# EQEP0_REG register map
Vendor: Texas Instruments
Peripheral module from a debugger description file (folder J7VCL).
Registers are 32-bit, read-write, reset 0x0 unless marked. A register's access mark holds for its fields unless they carry their own. Offsets are as the file gives them; lines under a group give offsets from that group; [hi:lo] are bit positions; {n}, {i} and the like mark numbered series; 'fields as' and 'values as' point back to an identical list; <NAME> marks a mode.

## EQEP0_REG
0x00 EQEP_QPOSCNT — QEP Position Counter register
  [31:0] POSCNT — This 32-bit Position Counter register counts up/down on every QEP pulse based on direction input.
0x04 EQEP_QPOSINIT — Position Counter Initialization register
  [31:0] INITPOS — This register contains the position value to be used to initialize the Position Counter based on external strobe or Index event.
0x08 EQEP_QPOSMAX — Maximum Position Count register
  [31:0] MAXPOS — This register contains the maximum Position Counter value for error checking in index reset mode or to reset the Position Counter based on the maximum count value.
0x0C EQEP_QPOSCMP — Position Compare register
  [31:0] POSCMP — Position compare value in this register is compared with the Position Counter (
0x10 EQEP_QPOSILAT ro — Index Position Latch register
  [31:0] IPOSLAT — Position Counter value can be latched into this register on index event as defined by the
0x14 EQEP_QPOSSLAT ro — Strobe Position Latch register
  [31:0] SPOSLAT — Position Counter value can be latched into this register on strobe event as defined by the
0x18 EQEP_QPOSLAT ro — QEP Position Counter Latch register
  [31:0] POSLAT — Position Counter value can be latched into this register on unit time out event.
0x1C EQEP_QUTMR — QEP Unit Timer register
  [31:0] UNITTMR — This register acts as time base for unit time event generation.
0x20 EQEP_QUPRD — QEP Unit Period register
  [31:0] UNITPRD — This register contains the period count for unit timer to generate periodic unit time events to latch the EQEP position information at periodic interval and optionally to generate interrupt.
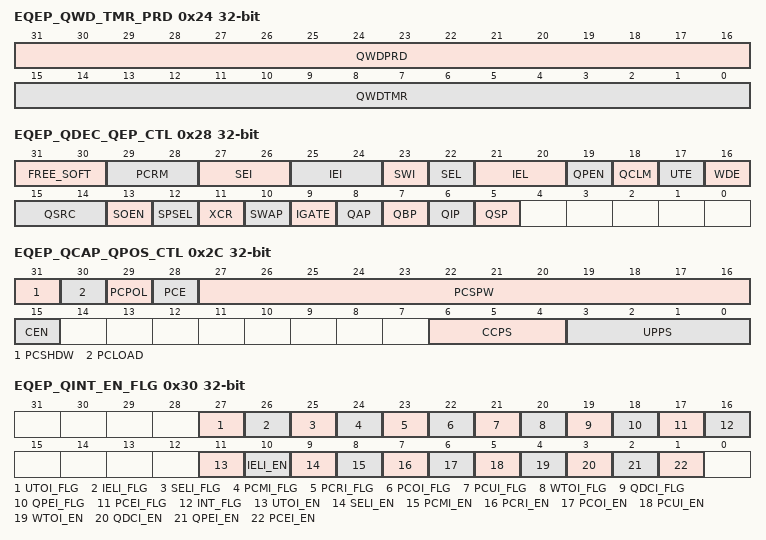
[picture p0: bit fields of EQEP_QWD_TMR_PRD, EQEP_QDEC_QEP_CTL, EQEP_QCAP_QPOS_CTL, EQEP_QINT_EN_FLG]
0x24 EQEP_QWD_TMR_PRD — QEP Watchdog Timer and Period register
  [31:16] QWDPRD — This field contains the time-out count for the QEP peripheral watch dog timer.
  [15:0] QWDTMR — This field acts as time base for watch dog to detect stalls.
0x28 EQEP_QDEC_QEP_CTL access per field — Quadrature Decoder and QEP Control register
  [31:30] FREE_SOFT rw — POSCNT Behavior:
  [29:28] PCRM rw — Position Counter Reset Mode:
  [27:26] SEI rw — Strobe Event Initialization of Position Counter:
  [25:24] IEI rw — Index Event Initialization of Position Counter:
  [23] SWI rw — Software Initialization of Position Counter:
  [22] SEL rw — Strobe Event Latch of Position Counter:
  [21:20] IEL rw — Index Event Latch of Position Counter (Software Index Marker):
  [19] QPEN rw — Quadrature Position Counter Enable/Software Reset:
  [18] QCLM rw — EQEP Capture Latch Mode:
  [17] UTE rw — QEP Unit Timer Enable:
  [16] WDE rw — QEP Watchdog Enable:
  [15:14] QSRC rw — Position Counter Source selection:
  [13] SOEN rw — Enable Position Compare Sync Output:
  [12] SPSEL rw — Sync Output Pin Selection:
  [11] XCR rw — External Clock Rate:
  [10] SWAP rw — CLK/DIR Signal Source for Position Counter:
  [9] IGATE rw — Index Pulse Gating Option:
  [8] QAP rw — QEPA Input Polarity:
  [7] QBP rw — QEPB Input Polarity:
  [6] QIP rw — QEPI Input Polarity:
  [5] QSP rw — QEPS Input Polarity:
0x2C EQEP_QCAP_QPOS_CTL access per field — QEP Capture and Position Compare Control register
  [31] PCSHDW rw — Position-Compare Shadow Enable:
  [30] PCLOAD rw — Position Compare Shadow Load Mode:
  [29] PCPOL rw — Polarity of Sync Output:
  [28] PCE rw — Position Compare Enable/Disable:
  [27:16] PCSPW rw — Select Pulse Width Period in EQEP_FICLK Cycles:
  [15] CEN rw — Enable EQEP Capture:
  [6:4] CCPS rw — EQEP Capture Timer Clock Prescalar:
  [3:0] UPPS rw — Unit Position Event Prescalar:
0x30 EQEP_QINT_EN_FLG access per field — QEP Interrupt Control and Flag register
  [27] UTOI_FLG ro — Unit Time Out Interrupt Flag:
  [26] IELI_FLG ro — Index Event Latch Interrupt Flag:
  [25] SELI_FLG ro — Strobe Event Latch Interrupt Flag:
  [24] PCMI_FLG ro — EQEP Compare Match Event Interrupt Flag:
  [23] PCRI_FLG ro — Position Compare Ready Interrupt Flag:
  [22] PCOI_FLG ro — Position Counter Overflow Interrupt Flag:
  [21] PCUI_FLG ro — Position Counter Underflow Interrupt Flag:
  [20] WTOI_FLG ro — Watchdog Timeout Interrupt Flag:
  [19] QDCI_FLG ro — Quadrature Direction Change Interrupt Flag:
  [18] QPEI_FLG ro — Quadrature Phase Error Interrupt Flag:
  [17] PCEI_FLG ro — Position Counter Error Interrupt Flag:
  [16] INT_FLG ro — Global Interrupt Status Flag:
  [11] UTOI_EN rw — Unit Time Out Interrupt Enable:
  [10] IELI_EN rw — Index Event Latch Interrupt Enable:
  [9] SELI_EN rw — Strobe Event Latch Interrupt Enable:
  [8] PCMI_EN rw — Position Compare Match Interrupt Enable:
  [7] PCRI_EN rw — Position Compare Ready Interrupt Enable:
  [6] PCOI_EN rw — Position Counter Overflow Interrupt Enable:
  [5] PCUI_EN rw — Position Counter Underflow Interrupt Enable:
  [4] WTOI_EN rw — Watchdog Time Out Interrupt Enable:
  [3] QDCI_EN rw — Quadrature Direction Change Interrupt Enable:
  [2] QPEI_EN rw — Quadrature Phase Error Interrupt Enable:
  [1] PCEI_EN rw — Position Counter Error Interrupt Enable:
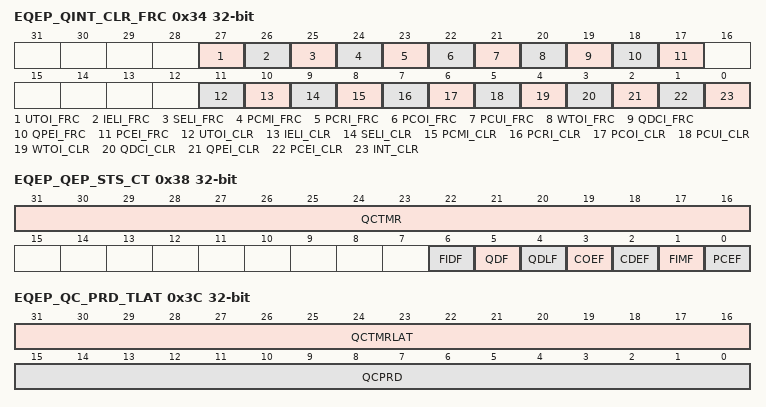
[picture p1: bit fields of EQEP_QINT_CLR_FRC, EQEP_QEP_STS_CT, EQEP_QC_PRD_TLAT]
0x34 EQEP_QINT_CLR_FRC access not given — QEP Interrupt Clear and Forcing register
  [27] UTOI_FRC — Unit Time Out Interrupt Force: (access W1S)
  [26] IELI_FRC — Index Event Latch Interrupt Force: (access W1S)
  [25] SELI_FRC — Strobe Event Latch Interrupt Force: (access W1S)
  [24] PCMI_FRC — Position Compare Match Interrupt Force: (access W1S)
  [23] PCRI_FRC — Position Compare Ready Interrupt Force: (access W1S)
  [22] PCOI_FRC — Position Counter Overflow Interrupt Force: (access W1S)
  [21] PCUI_FRC — Position Counter Underflow Interrupt Force: (access W1S)
  [20] WTOI_FRC — Watchdog Time Out Interrupt Force: (access W1S)
  [19] QDCI_FRC — Quadrature Direction Change Interrupt Force: (access W1S)
  [18] QPEI_FRC — Quadrature Phase Error Interrupt Force: (access W1S)
  [17] PCEI_FRC — Position Counter Error Interrupt Force: (access W1S)
  [11] UTOI_CLR — Clear Unit Time Out Interrupt Flag: (access W1C)
  [10] IELI_CLR — Clear Index Event Latch Interrupt Flag: (access W1C)
  [9] SELI_CLR — Clear Strobe Event Latch Interrupt Flag: (access W1C)
  [8] PCMI_CLR — Clear QEP Compare Match Event Interrupt Flag: (access W1C)
  [7] PCRI_CLR — Clear Position Compare Ready Interrupt Flag: (access W1C)
  [6] PCOI_CLR — Clear Position Counter Overflow Interrupt Flag: (access W1C)
  [5] PCUI_CLR — Clear Position Counter Underflow Interrupt Flag: (access W1C)
  [4] WTOI_CLR — Clear Watchdog Timeout Interrupt Flag: (access W1C)
  [3] QDCI_CLR — Clear Quadrature Direction Change Interrupt Flag: (access W1C)
  [2] QPEI_CLR — Clear Quadrature Phase Error Interrupt Flag: (access W1C)
  [1] PCEI_CLR — Clear Position Counter Error Interrupt Flag: (access W1C)
  [0] INT_CLR — Global Interrupt Clear Flag: (access W1C)
0x38 EQEP_QEP_STS_CT access not given — QEP Status and Capture Timer register
  [31:16] QCTMR rw — This field provides time base for edge capture unit.
  [6] FIDF ro — Direction on First Index Marker
  [5] QDF ro — Quadrature Direction Flag
  [4] QDLF ro — EQEP Direction Latch Flag
  [3] COEF — Capture Overflow Error Flag (access RW1C)
  [2] CDEF — Capture Direction Error Flag 1h = Direction change occurred between the capture position event (access RW1C)
  [1] FIMF — First Index Marker Flag (access RW1C)
  [0] PCEF ro — Position Counter Error Flag
0x3C EQEP_QC_PRD_TLAT access per field — QEP Capture Period and Timer Latch register
  [31:16] QCTMRLAT ro — EQEP Capture Timer value can be latched into this register on two events:
  [15:0] QCPRD rw — This field holds the period count value between the last successive EQEP position events.
0x40 EQEP_QCPRDLAT ro — QEP Capture Period Latch register
  [15:0] QCPRDLAT — EQEP capture period value can be latched into this register on two events:
0x5C EQEP_PID ro reset 0x44D31903 — Peripheral ID register
  [31:0] REVISION — TI Internal Data
